# LCM32F039 register map
File version: 1.0
CPU: CM0 r1p0, little endian, MPU, no FPU, 3 interrupt priority bits
Registers are 32-bit, read-write, reset 0x0 unless marked. A register's access mark holds for its fields unless they carry their own. Offsets are from the block's base; [hi:lo] are bit positions.

## I2C0 — I2C communication interface
Base 0x40013000
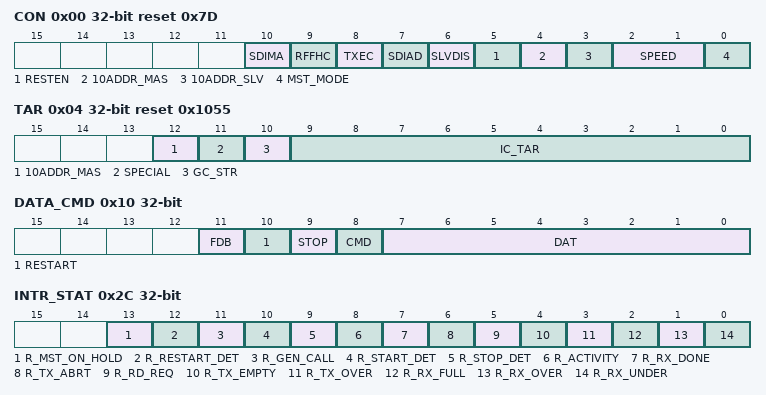
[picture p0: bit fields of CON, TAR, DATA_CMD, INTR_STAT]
0x00 CON reset 0x7D — I2C Control
  [10] SDIMA, [9] RFFHC, [8] TXEC, [7] SDIAD, [6] SLVDIS, [5] RESTEN, [4] 10ADDR_MAS, [3] 10ADDR_SLV, [2:1] SPEED, [0] MST_MODE
0x04 TAR reset 0x1055 — I2C Target Address
  [12] 10ADDR_MAS, [11] SPECIAL, [10] GC_STR, [9:0] IC_TAR
0x08 SAR reset 0x55 — I2C Slave Address
  [9:0] IC_SAR
0x10 DATA_CMD — I2C Rx/Tx Data Buffer and Command
  [11] FDB, [10] RESTART, [9] STOP, [8] CMD, [7:0] DAT
0x14 SSHCNT reset 0x11E — Standard speed I2C Clock SCL High Count
  [15:0] SS_SCL_HCNT
0x18 SSLCNT reset 0x150 — Standard speed I2C Clock SCL High Count
  [15:0] SS_SCL_LCNT
0x1C FSHCNT reset 0x2B — Fast Mode and Fast Mode Plus I2C Clock SCL
  [15:0] FS_SCL_HCNT — The fractional baud rate divisor.
0x20 FSLCNT reset 0x5D — Fast Mode and Fast Mode Plus I2C Clock SCL
  [15:0] FS_SCL_LCNT
0x2C INTR_STAT ro — I2C Interrupt Status
  [13] R_MST_ON_HOLD, [12] R_RESTART_DET, [11] R_GEN_CALL, [10] R_START_DET, [9] R_STOP_DET, [8] R_ACTIVITY, [7] R_RX_DONE, [6] R_TX_ABRT, [5] R_RD_REQ, [4] R_TX_EMPTY, [3] R_TX_OVER, [2] R_RX_FULL, [1] R_RX_OVER, [0] R_RX_UNDER
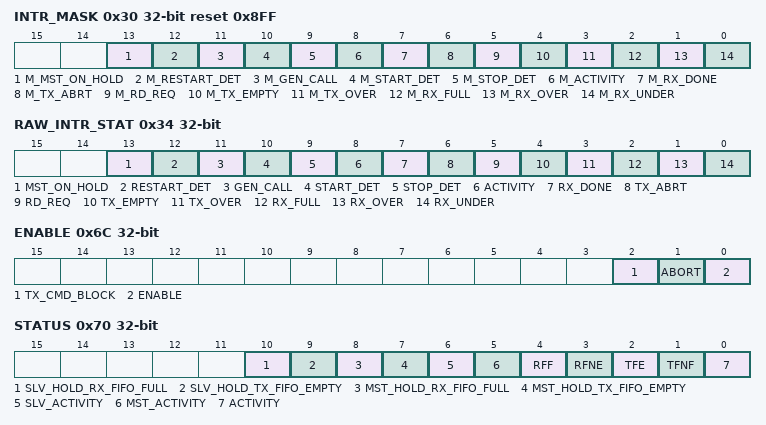
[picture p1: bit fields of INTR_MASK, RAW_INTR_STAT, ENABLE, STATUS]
0x30 INTR_MASK reset 0x8FF — I2C Interrupt Mask
  [13] M_MST_ON_HOLD, [12] M_RESTART_DET, [11] M_GEN_CALL, [10] M_START_DET, [9] M_STOP_DET, [8] M_ACTIVITY, [7] M_RX_DONE, [6] M_TX_ABRT, [5] M_RD_REQ, [4] M_TX_EMPTY, [3] M_TX_OVER, [2] M_RX_FULL, [1] M_RX_OVER, [0] M_RX_UNDER
0x34 RAW_INTR_STAT ro — I2C Raw Interrupt Status
  [13] MST_ON_HOLD, [12] RESTART_DET, [11] GEN_CALL, [10] START_DET, [9] STOP_DET, [8] ACTIVITY, [7] RX_DONE, [6] TX_ABRT, [5] RD_REQ, [4] TX_EMPTY, [3] TX_OVER, [2] RX_FULL, [1] RX_OVER, [0] RX_UNDER
0x38 RX_TL — I2C Receive FIFO Threshold
  [2:0] RX_TL — Receive FIFO Threshold Level
0x3C TX_TL — I2C Transmit FIFO Threshold
  [2:0] TX_TL — Transmit FIFO Threshold Level
0x40 CLR_INTR ro — Clear Combined and Individual Interrupts
  [0] CLR_INTR
0x44 CLR_RX_UNDER ro — Clear RX_UNDER Interrupt
  [0] CLR_RX_UNDER
0x48 CLR_RX_OVER ro — RX_OVER Interrupt
  [0] CLR_RX_OVER
0x4C CLR_TX_OVER ro — Clear TX_OVER Interrupt
  [0] CLR_TX_OVER
0x50 CLR_RD_REQ ro — Clear RD_REQ Interrupt
  [0] CLR_RD_REQ
0x54 CLR_TX_ABRT ro — Clear TX_ABRT Interrupt
  [0] CLR_TX_ABRT
0x58 CLR_RX_DONE ro — Clear RX_DONE Interrupt
  [0] CLR_RX_DONE
0x5C CLR_ACTIVITY ro — Clear ACTIVITY Interrupt
  [0] CLR_ACTIVITY
0x60 CLR_STOP_DET ro — Clear STOP_DET Interrupt
  [0] CLR_STOP_DET
0x64 CLR_START_DET ro — Clear START_DET Interrupt
  [0] CLR_START_DET
0x68 CLR_GEN_CALL ro — Clear GEN_CALL Interrupt
  [0] CLR_GEN_CALL
0x6C ENABLE — I2C Enable
  [2] TX_CMD_BLOCK, [1] ABORT, [0] ENABLE
0x70 STATUS ro — I2C Status register
  [10] SLV_HOLD_RX_FIFO_FULL
  [9] SLV_HOLD_TX_FIFO_EMPTY
  [8] MST_HOLD_RX_FIFO_FULL
  [7] MST_HOLD_TX_FIFO_EMPTY
  [6] SLV_ACTIVITY — Slave FSM Activity Status.
  [5] MST_ACTIVITY — Master FSM Activity Status.
  [4] RFF — Receive FIFO Completely Full
  [3] RFNE — Receive FIFO Not Empty.
  [2] TFE — Transmit FIFO Completely Empty.
  [1] TFNF — Transmit FIFO Not Full
  [0] ACTIVITY — I2C Activity Status.
0x74 TXFLR ro — Transmit FIFO Level Register
  [3:0] TXFLR
0x78 RXFLR ro — Receive FIFO Level Register
  [3:0] RXFLR
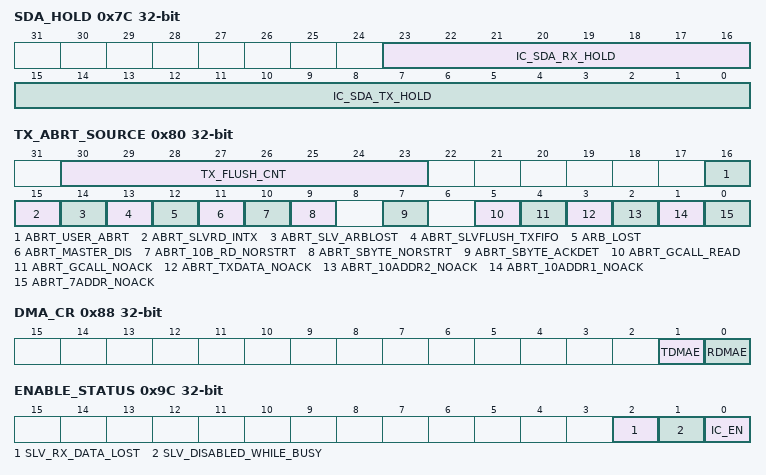
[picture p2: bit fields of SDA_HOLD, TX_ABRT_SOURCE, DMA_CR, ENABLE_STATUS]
0x7C SDA_HOLD — SDA hold time length register
  [23:16] IC_SDA_RX_HOLD, [15:0] IC_SDA_TX_HOLD
0x80 TX_ABRT_SOURCE ro — I2C Transmit Abort Status Register
  [30:23] TX_FLUSH_CNT, [16] ABRT_USER_ABRT, [15] ABRT_SLVRD_INTX, [14] ABRT_SLV_ARBLOST, [13] ABRT_SLVFLUSH_TXFIFO, [12] ARB_LOST, [11] ABRT_MASTER_DIS, [10] ABRT_10B_RD_NORSTRT, [9] ABRT_SBYTE_NORSTRT, [7] ABRT_SBYTE_ACKDET, [5] ABRT_GCALL_READ, [4] ABRT_GCALL_NOACK, [3] ABRT_TXDATA_NOACK, [2] ABRT_10ADDR2_NOACK, [1] ABRT_10ADDR1_NOACK, [0] ABRT_7ADDR_NOACK
0x84 SLV_DATA_NACK_ONLY — Generate SLV_DATA_NACK Register
  [0] NACK
0x88 DMA_CR — DMA Control Register for transmit and receive handshaking interface
  [1] TDMAE, [0] RDMAE
0x8C DMA_TDLR — DMA Transmit Data Level
  [2:0] DMATDL
0x90 DMA_RDLR — DMA Receive Data Level
  [2:0] DMARDL
0x94 SDA_SETUP reset 0x64 — I2C SDA Setup Register
  [7:0] SDA_SETUP
0x98 ACK_GENERAL_CALL reset 0x1 — I2C ACK General Call Register
  [0] ACK_GEN_CALL
0x9C ENABLE_STATUS ro — I2C Enable Status Register
  [2] SLV_RX_DATA_LOST, [1] SLV_DISABLED_WHILE_BUSY, [0] IC_EN
0xA0 FS_SPKLEN reset 0x4 — ISS and FS spike suppression limit
  [7:0] IC_FS_SPKLEN
0xA8 CLR_RESTARTDET ro — Clear RESTART_DET Interrupt
  [0] CLR_RESTART_DET
